# AUX_EVCTL register map
Vendor: Texas Instruments
Peripheral module from a debugger description file (folder CC26x0R2F).
Registers are 32-bit, access per field, reset 0x0 unless marked. A register's access mark holds for its fields unless they carry their own. Offsets are as the file gives them; lines under a group give offsets from that group; [hi:lo] are bit positions; {n}, {i} and the like mark numbered series; 'fields as' and 'values as' point back to an identical list; <NAME> marks a mode.

## AUX_EVCTL — AUX Event Controller
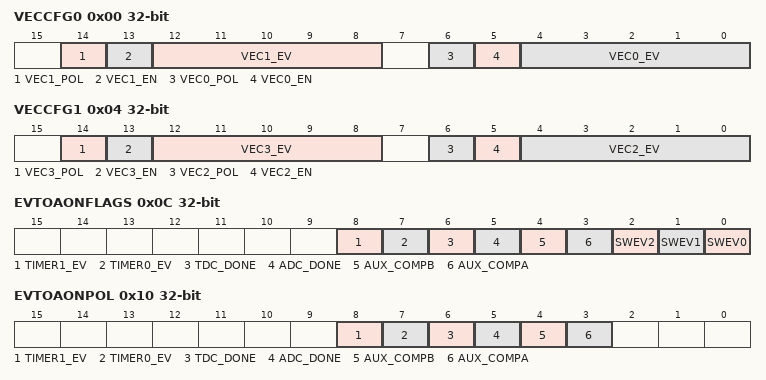
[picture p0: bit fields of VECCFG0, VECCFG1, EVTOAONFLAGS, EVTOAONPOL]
0x00 VECCFG0 — Vector Configuration 0 AUX_SCE wakeup vector 0 and 1 configuration
  [14] VEC1_POL rw — Vector 1 trigger event polarity. To manually trigger vector 1 execution: - AUX_SCE must sleep. - Set VEC1_EV to a known static value. - Toggle VEC1_POL twice.
    1=FALL (Falling edge triggers vector 1 execution.); 0=RISE (Rising edge triggers vector 1 execution.)
  [13] VEC1_EN rw — Vector 1 trigger enable. When enabled, VEC1_EV event with VEC1_POL polarity triggers a jump to vector # 1 when AUX_SCE sleeps. Lower vectors (0) have priority.
    1=EN (Enable vector 1 trigger.); 0=DIS (Disable vector 1 trigger.)
  [12:8] VEC1_EV rw — Select vector 1 trigger source event.
    31=ADC_IRQ (EVSTAT1.ADC_IRQ); 30=MCU_EV (EVSTAT1.MCU_EV); 29=ACLK_REF (EVSTAT1.ACLK_REF); {v}=AUXIO{v-13} (EVSTAT1.AUXIO{v-13}) (v=16..28); 15=AUXIO2 (EVSTAT0.AUXIO2); 14=AUXIO1 (EVSTAT0.AUXIO1); 13=AUXIO0 (EVSTAT0.AUXIO0); 12=AON_PROG_WU (EVSTAT0.AON_PROG_WU); 11=AON_SW (EVSTAT0.AON_SW); 10=OBSMUX1 (EVSTAT0.OBSMUX1); 9=OBSMUX0 (EVSTAT0.OBSMUX0); 8=ADC_FIFO_ALMOST_FULL (EVSTAT0.ADC_FIFO_ALMOST_FULL); 7=ADC_DONE (EVSTAT0.ADC_DONE); 6=SMPH_AUTOTAKE_DONE (EVSTAT0.SMPH_AUTOTAKE_DONE); 5=TIMER1_EV (EVSTAT0.TIMER1_EV); 4=TIMER0_EV (EVSTAT0.TIMER0_EV); 3=TDC_DONE (EVSTAT0.TDC_DONE); 2=AUX_COMPB (EVSTAT0.AUX_COMPB); 1=AUX_COMPA (EVSTAT0.AUX_COMPA); 0=AON_RTC_CH2 (EVSTAT0.AON_RTC_CH2)
  [6] VEC0_POL rw — Vector 0 trigger event polarity. To manually trigger vector 0 execution: - AUX_SCE must sleep. - Set VEC0_EV to a known static value. - Toggle VEC0_POL twice.
    1=FALL (Falling edge triggers vector 0 execution.); 0=RISE (Rising edge triggers vector 0 execution.)
  [5] VEC0_EN rw — Vector 0 trigger enable. When enabled, VEC0_EV event with VEC0_POL polarity triggers a jump to vector # 0 when AUX_SCE sleeps.
    1=EN (Enable vector 0 trigger.); 0=DIS (Disable vector 0 trigger.)
  [4:0] VEC0_EV rw — Select vector 0 trigger source event.
    values as VEC1_EV
0x04 VECCFG1 — Vector Configuration 1 AUX_SCE event vectors 2 and 3 configuration
  [14] VEC3_POL rw — Vector 3 trigger event polarity. To manually trigger vector 3 execution: - AUX_SCE must sleep. - Set VEC3_EV to a known static value. - Toggle VEC3_POL twice.
    1=FALL (Falling edge triggers vector 3 execution.); 0=RISE (Rising edge triggers vector 3 execution.)
  [13] VEC3_EN rw — Vector 3 trigger enable. When enabled, VEC3_EV event with VEC3_POL polarity triggers a jump to vector # 3 when AUX_SCE sleeps. Lower vectors (0, 1, and 2) have priority.
    1=EN (Enable vector 3 trigger.); 0=DIS (Disable vector 3 trigger.)
  [12:8] VEC3_EV rw — Select vector 3 trigger source event.
    values as VECCFG0.VEC1_EV
  [6] VEC2_POL rw — Vector 2 trigger event polarity. To manually trigger vector 2 execution: - AUX_SCE must sleep. - Set VEC2_EV to a known static value. - Toggle VEC2_POL twice.
    1=FALL (Falling edge triggers vector 2 execution.); 0=RISE (Rising edge triggers vector 2 execution.)
  [5] VEC2_EN rw — Vector 2 trigger enable. When enabled, VEC2_EV event with VEC2_POL polarity triggers a jump to vector # 2 when AUX_SCE sleeps. Lower vectors (0 and 1) have priority.
    1=EN (Enable vector 2 trigger.); 0=DIS (Disable vector 2 trigger.)
  [4:0] VEC2_EV rw — Select vector 2 trigger source event.
    values as VECCFG0.VEC1_EV
0x08 SCEWEVSEL — Sensor Controller Engine Wait Event Selection Configuration of this register controls bit index 7 in AUX_SCE:WUSTAT.EV_SIGNALS. This bit can be used by AUX_SCE WEV0, WEV1, BEV0 and BEV1 instructions
  [4:0] WEV7_EV rw — Select event source to connect to AUX_SCE:WUSTAT.EV_SIGNALS bit 7.
    values as VECCFG0.VEC1_EV
0x0C EVTOAONFLAGS — Events To AON Flags This register contains a collection of event flags routed to AON_EVENT. To clear an event flag, write to EVTOAONFLAGSCLR or write 0 to event flag in this register.
  [8] TIMER1_EV rw — This event flag is set when level selected by EVTOAONPOL.TIMER1_EV occurs on EVSTAT0.TIMER1_EV.
  [7] TIMER0_EV rw — This event flag is set when level selected by EVTOAONPOL.TIMER0_EV occurs on EVSTAT0.TIMER0_EV.
  [6] TDC_DONE rw — This event flag is set when level selected by EVTOAONPOL.TDC_DONE occurs on EVSTAT0.TDC_DONE.
  [5] ADC_DONE rw — This event flag is set when level selected by EVTOAONPOL.ADC_DONE occurs on EVSTAT0.ADC_DONE.
  [4] AUX_COMPB rw — This event flag is set when edge selected by EVTOAONPOL.AUX_COMPB occurs on EVSTAT0.AUX_COMPB.
  [3] AUX_COMPA rw — This event flag is set when edge selected by EVTOAONPOL.AUX_COMPA occurs on EVSTAT0.AUX_COMPA.
  [2] SWEV2 rw — This event flag is set when software writes a 1 to SWEVSET.SWEV2.
  [1] SWEV1 rw — This event flag is set when software writes a 1 to SWEVSET.SWEV1.
  [0] SWEV0 rw — This event flag is set when software writes a 1 to SWEVSET.SWEV0.
0x10 EVTOAONPOL — Events To AON Polarity Event source polarity configuration for EVTOAONFLAGS.
  [8] TIMER1_EV rw — Select the level of EVSTAT0.TIMER1_EV that sets EVTOAONFLAGS.TIMER1_EV.
    1=LOW (Low level); 0=HIGH (High level)
  [7] TIMER0_EV rw — Select the level of EVSTAT0.TIMER0_EV that sets EVTOAONFLAGS.TIMER0_EV.
    1=LOW (Low level); 0=HIGH (High level)
  [6] TDC_DONE rw — Select level of EVSTAT0.TDC_DONE that sets EVTOAONFLAGS.TDC_DONE.
    1=LOW (Low level); 0=HIGH (High level)
  [5] ADC_DONE rw — Select the level of EVSTAT0.ADC_DONE that sets EVTOAONFLAGS.ADC_DONE.
    1=LOW (Low level); 0=HIGH (High level)
  [4] AUX_COMPB rw — Select the edge of EVSTAT0.AUX_COMPB that sets EVTOAONFLAGS.AUX_COMPB.
    1=LOW (Falling edge); 0=HIGH (Rising edge)
  [3] AUX_COMPA rw — Select the edge of EVSTAT0.AUX_COMPA that sets EVTOAONFLAGS.AUX_COMPA.
    1=LOW (Falling edge); 0=HIGH (Rising edge)
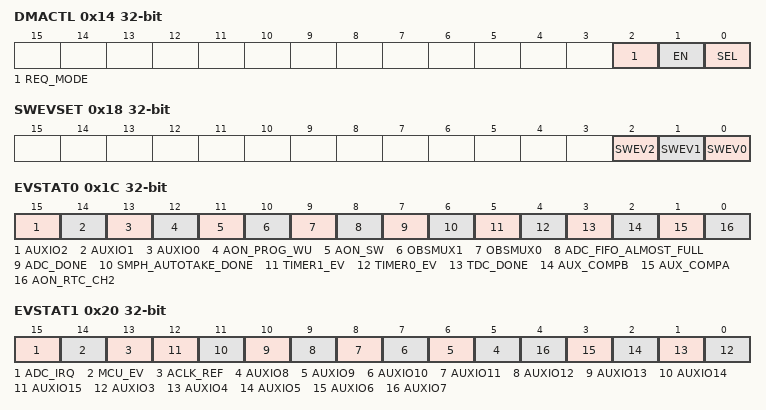
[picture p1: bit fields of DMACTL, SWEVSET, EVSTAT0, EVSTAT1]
0x14 DMACTL — Direct Memory Access Control
  [2] REQ_MODE rw — UDMA0 Request mode
    1=SINGLE (Single requests are generated on UDMA0 channel 7 when the condition configured in SEL is met.); 0=BURST (Burst requests are generated on UDMA0 channel 7 when the condition configured in SEL is met.)
  [1] EN rw — uDMA ADC interface enable. 0: Disable UDMA0 interface to ADC. 1: Enable UDMA0 interface to ADC.
  [0] SEL rw — Select FIFO watermark level required to trigger a UDMA0 transfer of ADC FIFO data.
    1=FIFO_ALMOST_FULL (UDMA0 trigger event will be generated when the ADC FIFO is almost full (3/4 full).); 0=FIFO_NOT_EMPTY (UDMA0 trigger event will be generated when there are samples in the ADC FIFO.)
0x18 SWEVSET — Software Event Set Set software event flags from AUX domain to AON and MCU domains. CPUs in MCU domain can read the event flags from EVTOAONFLAGS and clear them in EVTOAONFLAGSCLR. Use of these event flags is software-defined.
  [2] SWEV2 wo — Software event flag 2. 0: No effect. 1: Set software event flag 2.
  [1] SWEV1 wo — Software event flag 1. 0: No effect. 1: Set software event flag 1.
  [0] SWEV0 wo — Software event flag 0. 0: No effect. 1: Set software event flag 0.
0x1C EVSTAT0 ro — Event Status 0 Register holds events 0 thru 15 of the 32-bit event bus that is synchronous to AUX clock. The following subscribers use the asynchronous version of events in this register. - AUX_ANAIF. - AUX_TDC.
  [15] AUXIO2 — AUXIO2 pin level, read value corresponds to AUX_AIODIO0:GPIODIN bit 2.
  [14] AUXIO1 — AUXIO1 pin level, read value corresponds to AUX_AIODIO0:GPIODIN bit 1.
  [13] AUXIO0 — AUXIO0 pin level, read value corresponds to AUX_AIODIO0:GPIODIN bit 0.
  [12] AON_PROG_WU — AON_EVENT:AUXWUSEL.WU2_EV OR AON_EVENT:AUXWUSEL.WU1_EV OR AON_EVENT:AUXWUSEL.WU0_EV
  [11] AON_SW — AON_WUC:AUXCTL.SWEV
  [10] OBSMUX1 — Observation input 1 from IOC. This event is configured by IOC:OBSAUXOUTPUT.SEL1.
  [9] OBSMUX0 — Observation input 0 from IOC. This event is configured by IOC:OBSAUXOUTPUT.SEL0 and can be overridden by IOC:OBSAUXOUTPUT.SEL_MISC.
  [8] ADC_FIFO_ALMOST_FULL — AUX_ANAIF:ADCFIFOSTAT.ALMOST_FULL
  [7] ADC_DONE — AUX_ANAIF ADC conversion done event.
  [6] SMPH_AUTOTAKE_DONE — See AUX_SMPH:AUTOTAKE.SMPH_ID for description.
  [5] TIMER1_EV — AUX_TIMER1_EV event, see AUX_TIMER:T1TARGET for description.
  [4] TIMER0_EV — AUX_TIMER0_EV event, see AUX_TIMER:T0TARGET for description.
  [3] TDC_DONE — AUX_TDC:STAT.DONE
  [2] AUX_COMPB — Comparator B output
  [1] AUX_COMPA — Comparator A output
  [0] AON_RTC_CH2 — AON_RTC:EVFLAGS.CH2
0x20 EVSTAT1 ro — Event Status 1 Current event source levels, 31:16
  [15] ADC_IRQ — The logical function for this event is configurable. When DMACTL.EN = 1 : Event = UDMA0 Channel 7 done event OR AUX_ANAIF:ADCFIFOSTAT.OVERFLOW OR AUX_ANAIF:ADCFIFOSTAT.UNDERFLOW When DMACTL.EN = 0 : Event = (NOT AUX_ANAIF:ADCFIFOSTAT.EMPTY) OR AUX_ANAIF:ADCFIFOSTAT.OVERFLOW OR AUX_ANAIF:ADCFIFOSTAT.UNDERFLOW Bit 7 in UDMA0:DONEMASK must be 0.
  [14] MCU_EV — Event from EVENT configured by EVENT:AUXSEL0.
  [13] ACLK_REF — TDC reference clock. It is configured by DDI_0_OSC:CTL0.ACLK_REF_SRC_SEL and enabled by AUX_WUC:REFCLKCTL.REQ.
  [n-3] AUXIO{n} (n=8..15) — AUXIO{n} pin level, read value corresponds to AUX_AIODIO1:GPIODIN bit {n-8}.
  [n-3] AUXIO{n} (n=3..7) — AUXIO{n} pin level, read value corresponds to AUX_AIODIO0:GPIODIN bit {n}.
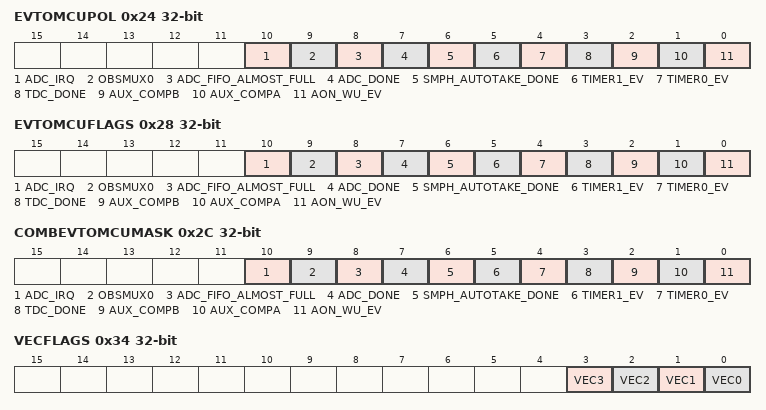
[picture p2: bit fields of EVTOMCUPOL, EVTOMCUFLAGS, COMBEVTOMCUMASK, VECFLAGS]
0x24 EVTOMCUPOL — Event To MCU Polarity Event source polarity configuration for EVTOMCUFLAGS.
  [all] fields
    1=LOW (Low level); 0=HIGH (High level)
  [10] ADC_IRQ rw — Select the event source level that sets EVTOMCUFLAGS.ADC_IRQ.
  [9] OBSMUX0 rw — Select the event source level that sets EVTOMCUFLAGS.OBSMUX0.
  [8] ADC_FIFO_ALMOST_FULL rw — Select the event source level that sets EVTOMCUFLAGS.ADC_FIFO_ALMOST_FULL.
  [7] ADC_DONE rw — Select the event source level that sets EVTOMCUFLAGS.ADC_DONE.
  [6] SMPH_AUTOTAKE_DONE rw — Select the event source level that sets EVTOMCUFLAGS.SMPH_AUTOTAKE_DONE.
  [5] TIMER1_EV rw — Select the event source level that sets EVTOMCUFLAGS.TIMER1_EV.
  [4] TIMER0_EV rw — Select the event source level that sets EVTOMCUFLAGS.TIMER0_EV.
  [3] TDC_DONE rw — Select the event source level that sets EVTOMCUFLAGS.TDC_DONE.
  [2] AUX_COMPB rw — Select the event source level that sets EVTOMCUFLAGS.AUX_COMPB.
  [1] AUX_COMPA rw — Select the event source level that sets EVTOMCUFLAGS.AUX_COMPA.
  [0] AON_WU_EV rw — Select the event source level that sets EVTOMCUFLAGS.AON_WU_EV.
0x28 EVTOMCUFLAGS — Events to MCU Flags This register contains a collection of event flags routed to MCU domain. To clear an event flag, write to EVTOMCUFLAGSCLR or write 0 to event flag in this register. Follow procedure described in AUX_SYSIF:WUCLR to clear AUX_WU_EV event flag.
  [10] ADC_IRQ rw — This event flag is set when level selected by EVTOMCUPOL.ADC_IRQ occurs on EVSTAT0.ADC_IRQ.
  [9] OBSMUX0 rw — This event flag is set when level selected by EVTOMCUPOL.MCU_OBSMUX0 occurs on EVSTAT0.MCU_OBSMUX0.
  [8] ADC_FIFO_ALMOST_FULL rw — This event flag is set when level selected by EVTOMCUPOL.ADC_FIFO_ALMOST_FULL occurs on EVSTAT0.ADC_FIFO_ALMOST_FULL.
  [7] ADC_DONE rw — This event flag is set when level selected by EVTOMCUPOL.ADC_DONE occurs on EVSTAT0.ADC_DONE.
  [6] SMPH_AUTOTAKE_DONE rw — This event flag is set when level selected by EVTOMCUPOL.SMPH_AUTOTAKE_DONE occurs on EVSTAT0.SMPH_AUTOTAKE_DONE.
  [5] TIMER1_EV rw — This event flag is set when level selected by EVTOMCUPOL.TIMER1_EV occurs on EVSTAT0.TIMER1_EV.
  [4] TIMER0_EV rw — This event flag is set when level selected by EVTOMCUPOL.TIMER0_EV occurs on EVSTAT0.TIMER0_EV.
  [3] TDC_DONE rw — This event flag is set when level selected by EVTOMCUPOL.TDC_DONE occurs on EVSTAT0.TDC_DONE.
  [2] AUX_COMPB rw — This event flag is set when edge selected by EVTOMCUPOL.AUX_COMPB occurs on EVSTAT0.AUX_COMPB.
  [1] AUX_COMPA rw — This event flag is set when edge selected by EVTOMCUPOL.AUX_COMPA occurs on EVSTAT0.AUX_COMPA.
  [0] AON_WU_EV rw — This event flag is set when level selected by EVTOMCUPOL.AON_WU_EV occurs on the reduction-OR of the AUX_EVCTL:EVSTAT0.RTC_CH2_EV, AUX_EVCTL:EVSTAT0.AON_SW, and AUX_EVCTL:EVSTAT0.AON_PROG_WU events.
0x2C COMBEVTOMCUMASK — Combined Event To MCU Mask Select event flags in EVTOMCUFLAGS that contribute to the AUX_COMB event to EVENT and system CPU. The AUX_COMB event is high as long as one or more of the included event flags are set.
  [10] ADC_IRQ rw — EVTOMCUFLAGS.ADC_IRQ contribution to the AUX_COMB event. 0: Exclude. 1: Include.
  [9] OBSMUX0 rw — EVTOMCUFLAGS.MCU_OBSMUX0 contribution to the AUX_COMB event. 0: Exclude. 1: Include.
  [8] ADC_FIFO_ALMOST_FULL rw — EVTOMCUFLAGS.ADC_FIFO_ALMOST_FULL contribution to the AUX_COMB event. 0: Exclude. 1: Include.
  [7] ADC_DONE rw — EVTOMCUFLAGS.ADC_DONE contribution to the AUX_COMB event. 0: Exclude. 1: Include.
  [6] SMPH_AUTOTAKE_DONE rw — EVTOMCUFLAGS.SMPH_AUTOTAKE_DONE contribution to the AUX_COMB event. 0: Exclude. 1: Include.
  [5] TIMER1_EV rw — EVTOMCUFLAGS.TIMER1_EV contribution to the AUX_COMB event. 0: Exclude. 1: Include.
  [4] TIMER0_EV rw — EVTOMCUFLAGS.TIMER0_EV contribution to the AUX_COMB event. 0: Exclude. 1: Include.
  [3] TDC_DONE rw — EVTOMCUFLAGS.TDC_DONE contribution to the AUX_COMB event. 0: Exclude. 1: Include.
  [2] AUX_COMPB rw — EVTOMCUFLAGS.AUX_COMPB contribution to the AUX_COMB event. 0: Exclude 1: Include.
  [1] AUX_COMPA rw — EVTOMCUFLAGS.AUX_COMPA contribution to the AUX_COMB event. 0: Exclude. 1: Include.
  [0] AON_WU_EV rw — EVTOMCUFLAGS.AON_WU_EV contribution to the AUX_COMB event. 0: Exclude. 1: Include.
0x34 VECFLAGS — Vector Flags If a vector flag becomes 1 and AUX_SCE sleeps, AUX_SCE will wake up and execute the corresponding vector. The vector with the lowest index will execute first if multiple vectors flags are set. AUX_SCE must return to sleep to execute the next vector. During execution of a vector, AUX_SCE must clear the vector flag that triggered execution. Write 1 to bit index n in VECFLAGSCLR to clear vector flag n.
  [3] VEC3 rw — Vector flag 3. The vector flag is set if the edge selected VECCFG1.VEC3_POL occurs on the event selected in VECCFG1.VEC3_EV. The flag is cleared by writing a 0 to this bit, or (preferably) a 1 to VECFLAGSCLR.VEC3.
  [2] VEC2 rw — Vector flag 2. The vector flag is set if the edge selected VECCFG1.VEC2_POL occurs on the event selected in VECCFG1.VEC2_EV. The flag is cleared by writing a 0 to this bit, or (preferably) a 1 to VECFLAGSCLR.VEC2.
  [1] VEC1 rw — Vector flag 1. The vector flag is set if the edge selected VECCFG0.VEC1_POL occurs on the event selected in VECCFG0.VEC1_EV. The flag is cleared by writing a 0 to this bit, or (preferably) a 1 to VECFLAGSCLR.VEC1.
  [0] VEC0 rw — Vector flag 0. The vector flag is set if the edge selected VECCFG0.VEC0_POL occurs on the event selected in VECCFG0.VEC0_EV. The flag is cleared by writing a 0 to this bit, or (preferably) a 1 to VECFLAGSCLR.VEC0.
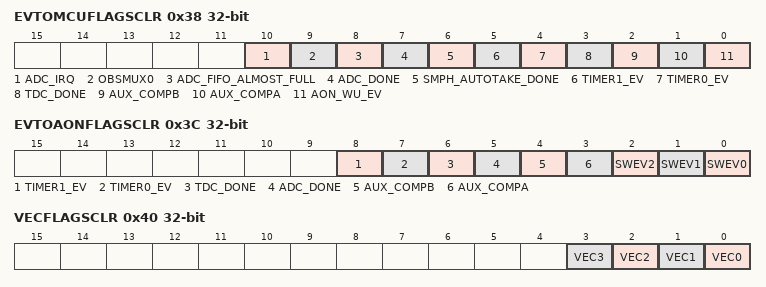
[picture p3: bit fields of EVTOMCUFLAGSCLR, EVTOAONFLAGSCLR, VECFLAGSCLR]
0x38 EVTOMCUFLAGSCLR — Events To MCU Flags Clear Clear event flags in EVTOMCUFLAGS. In order to clear a level sensitive event flag, the event must be deasserted.
  [10] ADC_IRQ wo — Write 1 to clear EVTOMCUFLAGS.ADC_IRQ. Read value is 0.
  [9] OBSMUX0 wo — Write 1 to clear EVTOMCUFLAGS.MCU_OBSMUX0. Read value is 0.
  [8] ADC_FIFO_ALMOST_FULL wo — Write 1 to clear EVTOMCUFLAGS.ADC_FIFO_ALMOST_FULL. Read value is 0.
  [7] ADC_DONE wo — Write 1 to clear EVTOMCUFLAGS.ADC_DONE. Read value is 0.
  [6] SMPH_AUTOTAKE_DONE wo — Write 1 to clear EVTOMCUFLAGS.SMPH_AUTOTAKE_DONE. Read value is 0.
  [5] TIMER1_EV wo — Write 1 to clear EVTOMCUFLAGS.TIMER1_EV. Read value is 0.
  [4] TIMER0_EV wo — Write 1 to clear EVTOMCUFLAGS.TIMER0_EV. Read value is 0.
  [3] TDC_DONE wo — Write 1 to clear EVTOMCUFLAGS.TDC_DONE. Read value is 0.
  [2] AUX_COMPB wo — Write 1 to clear EVTOMCUFLAGS.AUX_COMPB. Read value is 0.
  [1] AUX_COMPA wo — Write 1 to clear EVTOMCUFLAGS.AUX_COMPA. Read value is 0.
  [0] AON_WU_EV wo — Write 1 to clear EVTOMCUFLAGS.AON_WU_EV. Read value is 0.
0x3C EVTOAONFLAGSCLR — Events To AON Clear Clear event flags in EVTOAONFLAGS. In order to clear a level sensitive event flag, the event must be deasserted.
  [8] TIMER1_EV wo — Write 1 to clear EVTOAONFLAGS.TIMER1_EV. Read value is 0.
  [7] TIMER0_EV wo — Write 1 to clear EVTOAONFLAGS.TIMER0_EV. Read value is 0.
  [6] TDC_DONE wo — Write 1 to clear EVTOAONFLAGS.TDC_DONE. Read value is 0.
  [5] ADC_DONE wo — Write 1 to clear EVTOAONFLAGS.ADC_DONE. Read value is 0.
  [4] AUX_COMPB wo — Write 1 to clear EVTOAONFLAGS.AUX_COMPB. Read value is 0.
  [3] AUX_COMPA wo — Write 1 to clear EVTOAONFLAGS.AUX_COMPA. Read value is 0.
  [2] SWEV2 wo — Write 1 to clear EVTOAONFLAGS.SWEV2. Read value is 0.
  [1] SWEV1 wo — Write 1 to clear EVTOAONFLAGS.SWEV1. Read value is 0.
  [0] SWEV0 wo — Write 1 to clear EVTOAONFLAGS.SWEV0. Read value is 0.
0x40 VECFLAGSCLR — Vector Flags Clear Strobes for clearing flags in VECFLAGS.
  [n] VEC{n} wo (n=0..3) — Clear vector flag {n}. 0: No effect. 1: Clear VECFLAGS.VEC{n}. Read value is 0.
